VERSION ""

NS_ :

BS_:
BU_: EON XXX RDC SZL VGSG JBBF RFK FLA RAD1 CAS CID AHM HKL HUD EKP DWA DSC SM_BF GWS VDM DDE1 ACI CCC SM_FA CTM LDM RSE MRSZ VDA EDCK ZBE EGS ACC_Sensor Kombi IHKA ARS ACSM FZD PGS NVC AFS DME FRMFA EMF FKA VSW EPS PDC DKG EHC Diagnosetool_PT_CAN Diagnosetool_K_CAN_System ASCM
BO_ 168 Torque1: 8 DME
   SG_ CHK_SUM_TORQ_1_DME : 0|8@1+ (1,0) [0|255] "" XXX
   SG_ ALIV_TORQ_1_DME : 8|4@1+ (1,0) [0|1] "" XXX
   SG_ TORQ_AVL : 11|12@1- (0.5,0) [-1024|1023] "Nm" XXX
   SG_ ST_TORQ_AVL : 24|4@1+ (1,0) [-1024|1023.97] "" XXX
   SG_ TORQ_AVL_DMEE : 28|12@1- (0.5,0) [0|255] "Nm" XXX
   SG_ ST_DMEA_SWO : 44|2@1+ (1,0) [0|255] "" XXX
   SG_ RCPT_ACC_SWO_SYS_DME : 46|2@1+ (1,0) [0|255] "" XXX
   SG_ ST_RCPT_ENG_ACC : 48|2@1+ (1,0) [0|255] "" XXX
   SG_ ST_RCPT_ENG_ARS : 50|2@1+ (1,0) [0|255] "" XXX
   SG_ ST_RCPT_ENG_DSC : 52|2@1+ (1,0) [0|255] "" XXX
   SG_ ST_RCPT_ENG_EGS : 54|2@1+ (1,0) [0|255] "" XXX
   SG_ ST_OBD_CTFN_GRB : 56|5@1+ (1,0) [0|255] "" XXX
   SG_ ST_CT_BRPD_DME : 61|3@1+ (1,0) [0|255] "" XXX

BO_ 169 Torque2: 8 DME
   SG_ CHK_SUM_TORQ_2_DME : 0|8@1+ (1,0) [0|255] "" XXX
   SG_ ALIV_TORQ_2_DME : 8|4@1+ (1,0) [0|255] "" XXX
   SG_ ST_SW_LEV_RPM : 12|2@1+ (1,0) [0|255] "" XXX
   SG_ ST_INFS : 14|2@1+ (1,0) [0|255] "" XXX
   SG_ TORQ_AVL_MIN : 16|12@1- (0.5,0) [0|255] "Nm" XXX
   SG_ TORQ_AVL_MAX : 16|12@1- (0.5,0) [0|255] "Nm" XXX
   SG_ TORQ_AVL_SPAR_NEG : 16|12@1- (0.5,0) [0|255] "Nm" XXX
   SG_ TORQ_AVL_SPAR_POS : 16|12@1- (0.5,0) [0|255] "Nm" XXX

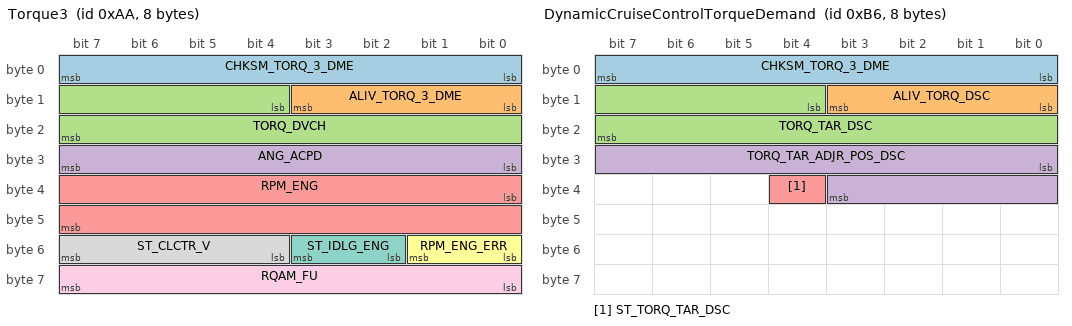
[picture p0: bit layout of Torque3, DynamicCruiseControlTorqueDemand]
BO_ 170 Torque3: 8 DME
   SG_ CHKSM_TORQ_3_DME : 0|8@1+ (1,0) [0|255] "" XXX
   SG_ ALIV_TORQ_3_DME : 8|4@1+ (1,0) [0|255] "" XXX
   SG_ TORQ_DVCH : 12|12@1- (0.5,0) [0|255] "Nm" XXX
   SG_ ANG_ACPD : 24|8@1+ (0.39063,0) [0|255] "%" XXX
   SG_ RPM_ENG : 32|16@1+ (0.25,0) [0|10000] "Rpm" XXX
   SG_ RPM_ENG_ERR : 48|2@1+ (1,0) [0|255] "" XXX
   SG_ ST_IDLG_ENG : 50|2@1+ (1,0) [0|255] "" XXX
   SG_ ST_CLCTR_V : 52|4@1+ (1,0) [0|255] "" XXX
   SG_ RQAM_FU : 56|8@1+ (1,0) [0|255] "" XXX

BO_ 182 DynamicCruiseControlTorqueDemand: 8 DSC
   SG_ CHKSM_TORQ_3_DME : 0|8@1+ (1,0) [0|255] "" XXX
   SG_ ALIV_TORQ_DSC : 8|4@1+ (1,0) [0|255] "" XXX
   SG_ TORQ_TAR_DSC : 12|12@1- (0.5,0) [0|255] "Nm" XXX
   SG_ TORQ_TAR_ADJR_POS_DSC : 24|12@1- (0.5,0) [0|255] "Nm" XXX
   SG_ ST_TORQ_TAR_DSC : 36|1@1+ (1,0) [0|255] "" XXX

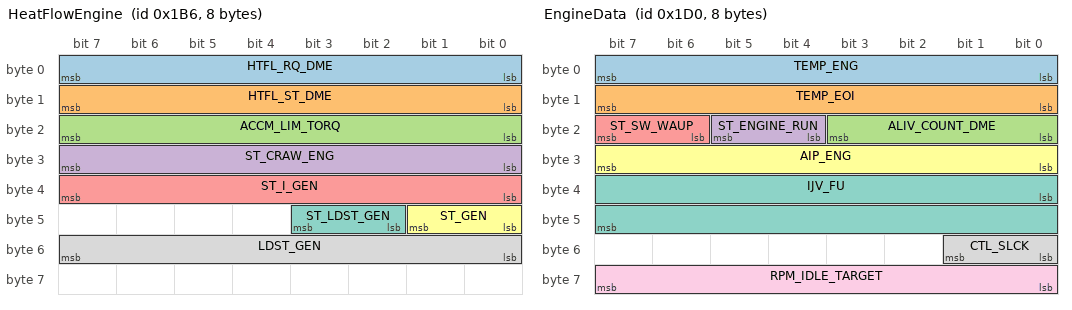
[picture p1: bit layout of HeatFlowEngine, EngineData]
BO_ 438 HeatFlowEngine: 8 DME
   SG_ HTFL_RQ_DME : 0|8@1+ (1,0) [0|255] "" XXX
   SG_ HTFL_ST_DME : 8|8@1+ (1,0) [0|255] "" XXX
   SG_ ACCM_LIM_TORQ : 16|8@1+ (0.5,0) [0|255] "Nm" XXX
   SG_ ST_CRAW_ENG : 24|8@1+ (1,0) [0|255] "A" XXX
   SG_ ST_I_GEN : 32|8@1+ (1,0) [0|255] "A" XXX
   SG_ ST_GEN : 40|2@1+ (1,0) [0|255] "" XXX
   SG_ ST_LDST_GEN : 42|2@1+ (1,0) [0|255] "" XXX
   SG_ LDST_GEN : 48|8@1+ (1,0) [0|255] "%" XXX

BO_ 464 EngineData: 8 DME
   SG_ TEMP_ENG : 0|8@1+ (1,-48) [0|255] "°C" XXX
   SG_ TEMP_EOI : 8|8@1+ (1,-48) [0|255] "°C" XXX
   SG_ ALIV_COUNT_DME : 16|4@1+ (1,0) [0|255] "" XXX
   SG_ ST_ENGINE_RUN : 20|2@1+ (1,0) [0|255] "" XXX
   SG_ ST_SW_WAUP : 22|2@1+ (1,0) [0|255] "" XXX
   SG_ AIP_ENG : 24|8@1+ (2,598) [0|255] "hPa" XXX
   SG_ IJV_FU : 32|16@1+ (1,0) [0|255] "µl" XXX
   SG_ CTL_SLCK : 48|2@1+ (1,0) [0|255] "" XXX
   SG_ RPM_IDLE_TARGET : 56|8@1+ (5,0) [0|255] "Rpm" XXX

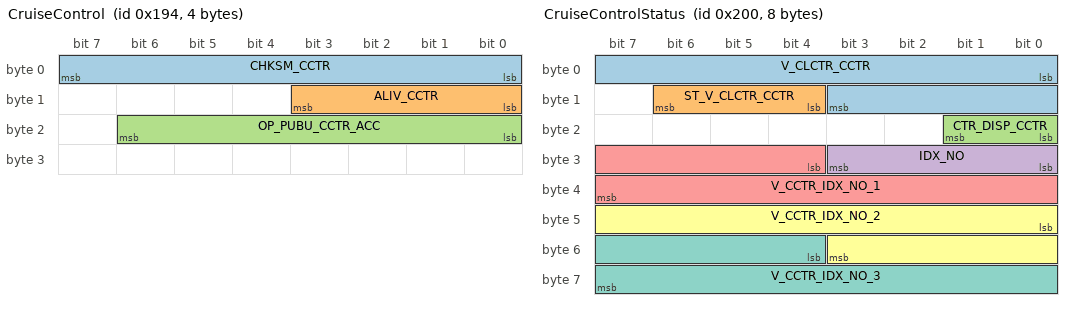
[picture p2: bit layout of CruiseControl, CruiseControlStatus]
BO_ 404 CruiseControl: 4 SZL
   SG_ CHKSM_CCTR : 0|8@1+ (1,0) [0|255] "" XXX
   SG_ ALIV_CCTR : 8|4@1+ (1,0) [0|255] "" XXX
   SG_ OP_PUBU_CCTR_ACC : 16|7@1+ (1,0) [0|255] "" XXX

BO_ 512 CruiseControlStatus: 8 DME
   SG_ V_CLCTR_CCTR : 0|12@1+ (0.1,0) [0|255] "kmph" XXX
   SG_ ST_V_CLCTR_CCTR : 12|3@1+ (1,0) [0|255] "" XXX
   SG_ CTR_DISP_CCTR : 16|2@1+ (0.1,0) [0|255] "kmph" XXX
   SG_ IDX_NO : 24|4@1+ (0.1,0) [0|255] "kmph" XXX
   SG_ V_CCTR_IDX_NO_1 : 28|12@1+ (0.1,0) [0|255] "kmph" XXX
   SG_ V_CCTR_IDX_NO_2 : 40|12@1+ (0.1,0) [0|255] "kmph" XXX
   SG_ V_CCTR_IDX_NO_3 : 52|12@1+ (0.1,0) [0|255] "kmph" XXX

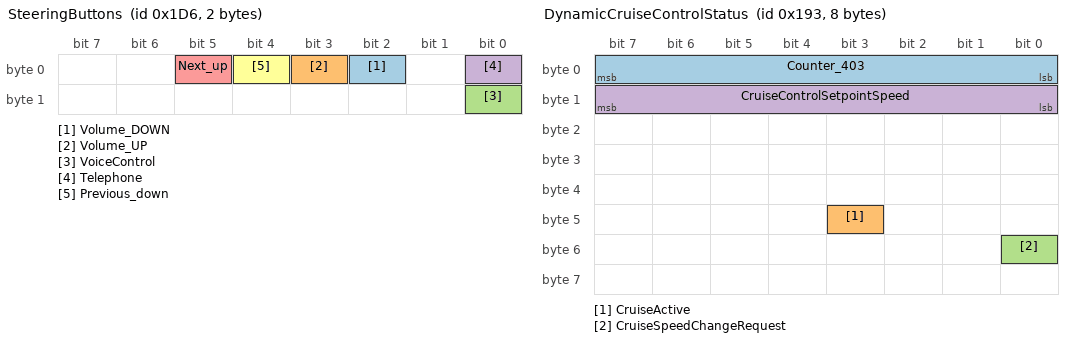
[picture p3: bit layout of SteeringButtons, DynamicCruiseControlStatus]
BO_ 470 SteeringButtons: 2 SZL
   SG_ Volume_DOWN : 2|1@0+ (1,0) [0|1] "" XXX
   SG_ Volume_UP : 3|1@0+ (1,0) [0|1] "" XXX
   SG_ VoiceControl : 8|1@0+ (1,0) [0|1] "" XXX
   SG_ Telephone : 0|1@0+ (1,0) [0|1] "" XXX
   SG_ Next_up : 5|1@0+ (1,0) [0|1] "" XXX
   SG_ Previous_down : 4|1@0+ (1,0) [0|1] "" XXX

BO_ 403 DynamicCruiseControlStatus: 8 DSC
   SG_ Counter_403 : 7|8@0+ (1,0) [0|255] "" XXX
   SG_ CruiseActive : 43|1@0+ (1,0) [0|1] "" XXX
   SG_ CruiseSpeedChangeRequest : 48|1@0+ (1,0) [0|1] "" XXX
   SG_ CruiseControlSetpointSpeed : 15|8@0+ (1,-2) [0|255] "kph/mph" XXX

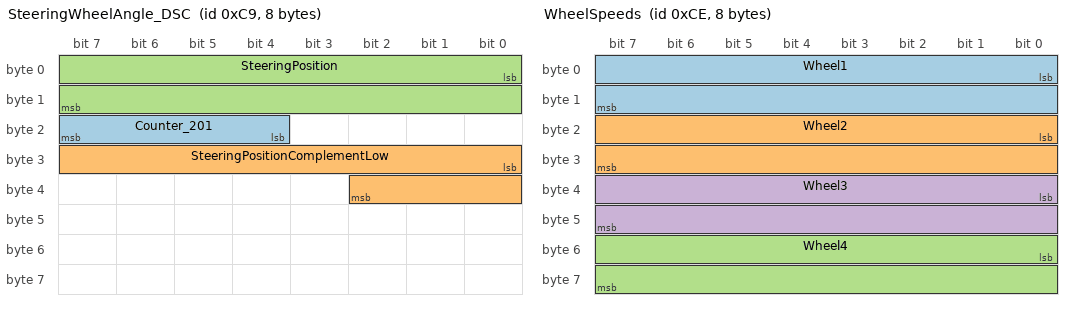
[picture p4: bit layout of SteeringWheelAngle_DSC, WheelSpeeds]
BO_ 201 SteeringWheelAngle_DSC: 8 SZL
   SG_ Counter_201 : 20|4@1+ (1,0) [0|15] "" DSC
   SG_ SteeringPositionComplementLow : 24|11@1- (1,0) [0|1] "" DSC
   SG_ SteeringPosition : 0|16@1- (0.0428317,0) [-600|600] "deg" DSC

BO_ 206 WheelSpeeds: 8 DSC
   SG_ Wheel1 : 0|16@1- (0.0625,0) [0|255] "kph" XXX
   SG_ Wheel2 : 16|16@1- (0.0625,0) [0|255] "kph" XXX
   SG_ Wheel4 : 48|16@1- (0.0625,0) [0|255] "kph" XXX
   SG_ Wheel3 : 32|16@1- (0.0625,0) [0|255] "kph" XXX

BO_ 884 WheelToleranceAdjustment: 8 DSC

BO_ 678 WiperSwitch: 8 SZL
   SG_ AutoWipersOn : 0|1@1+ (1,0) [0|3] "" XXX

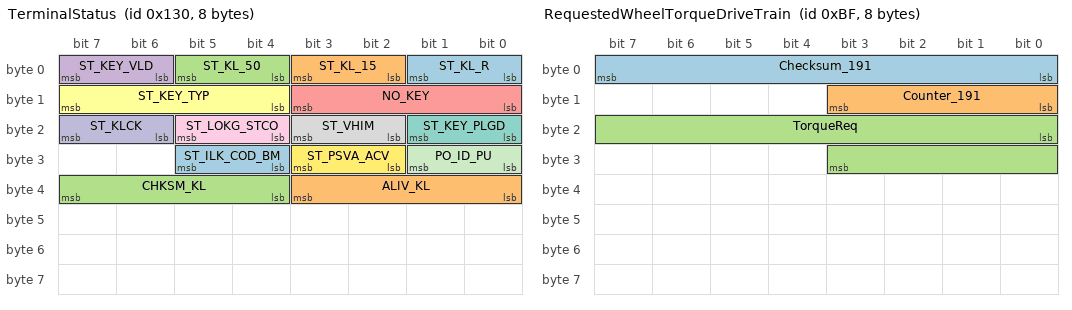
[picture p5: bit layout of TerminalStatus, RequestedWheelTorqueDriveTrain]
BO_ 304 TerminalStatus: 8 CAS
   SG_ ST_KL_R : 0|2@1+ (1,0) [0|3] "" XXX
   SG_ ST_KL_15 : 2|2@1+ (1,0) [0|3] "" XXX
   SG_ ST_KL_50 : 4|2@1+ (1,0) [0|3] "" XXX
   SG_ ST_KEY_VLD : 6|2@1+ (1,0) [0|3] "" XXX
   SG_ NO_KEY : 8|4@1+ (1,0) [0|3] "" XXX
   SG_ ST_KEY_TYP : 12|4@1+ (1,0) [0|3] "" XXX
   SG_ ST_KEY_PLGD : 16|2@1+ (1,0) [0|3] "" XXX
   SG_ ST_VHIM : 18|2@1+ (1,0) [0|3] "" XXX
   SG_ ST_LOKG_STCO : 20|2@1+ (1,0) [0|3] "" XXX
   SG_ ST_KLCK : 22|2@1+ (1,0) [0|3] "" XXX
   SG_ PO_ID_PU : 24|2@1+ (1,0) [0|3] "" XXX
   SG_ ST_PSVA_ACV : 26|2@1+ (1,0) [0|3] "" XXX
   SG_ ST_ILK_COD_BM : 28|2@1+ (1,0) [0|3] "" XXX
   SG_ ALIV_KL : 32|4@1+ (1,0) [0|3] "" XXX
   SG_ CHKSM_KL : 36|4@1+ (1,0) [0|3] "" XXX

BO_ 184 TorqueTransmisionRequest: 8 LDM
   SG_ Checksum_184 : 0|8@1+ (1,0) [0|15] "" XXX
   SG_ Counter_184 : 8|4@1+ (1,0) [0|15] "" XXX

BO_ 196 SteeringWheelAngle: 7 DSC
   SG_ SteeringSpeed : 24|16@1- (0.0428317,0) [0|255] "degree/s" XXX
   SG_ SteeringPosition : 0|16@1- (0.0428317,0) [-600|600] "degree" XXX

BO_ 180 WheelTorqueDriveTrain1: 8 DME

BO_ 186 TransmissionData: 8 EGS
   SG_ Counter_186 : 48|4@1+ (1,0) [0|14] "" XXX
   SG_ Checksum_186 : 40|4@1+ (1,0) [0|15] "" XXX

BO_ 191 RequestedWheelTorqueDriveTrain: 8 LDM
   SG_ Checksum_191 : 0|8@1+ (1,0) [0|19] "" XXX
   SG_ Counter_191 : 8|4@1- (1,0) [0|255] "" XXX
   SG_ TorqueReq : 16|12@1- (0.5,350) [-1024|1023.97] "" XXX

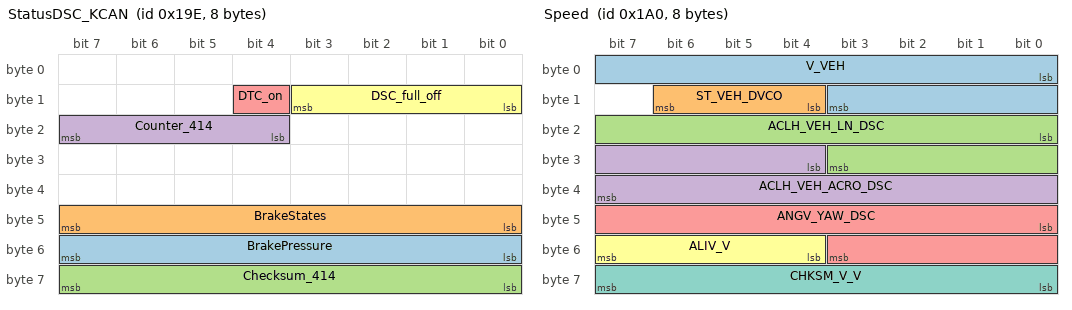
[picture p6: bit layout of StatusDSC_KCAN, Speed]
BO_ 414 StatusDSC_KCAN: 8 DSC
   SG_ BrakePressure : 48|8@1- (1,0) [0|255] "" XXX
   SG_ BrakeStates : 40|8@1+ (1,0) [0|255] "" XXX
   SG_ Checksum_414 : 56|8@1+ (1,0) [0|15] "" XXX
   SG_ Counter_414 : 20|4@1+ (1,0) [0|15] "" XXX
   SG_ DTC_on : 12|1@1+ (1,0) [0|3] "" XXX
   SG_ DSC_full_off : 8|4@1+ (1,0) [0|15] "" XXX

BO_ 416 Speed: 8 DSC
   SG_ V_VEH : 0|12@1+ (0.1,0) [0|255] "kph" XXX
   SG_ ST_VEH_DVCO : 12|3@1+ (1,0) [0|7] "" XXX
   SG_ ACLH_VEH_LN_DSC : 16|12@1- (0.025,0) [0|255] "m/s²" XXX
   SG_ ACLH_VEH_ACRO_DSC : 28|12@1- (0.025,0) [0|255] "m/s²" XXX
   SG_ ANGV_YAW_DSC : 40|12@1- (0.05,0) [0|255] "m/s²" XXX
   SG_ ALIV_V : 52|4@1+ (1,0) [0|14] "" XXX
   SG_ CHKSM_V_V : 56|8@1+ (1,0) [0|15] "" XXX

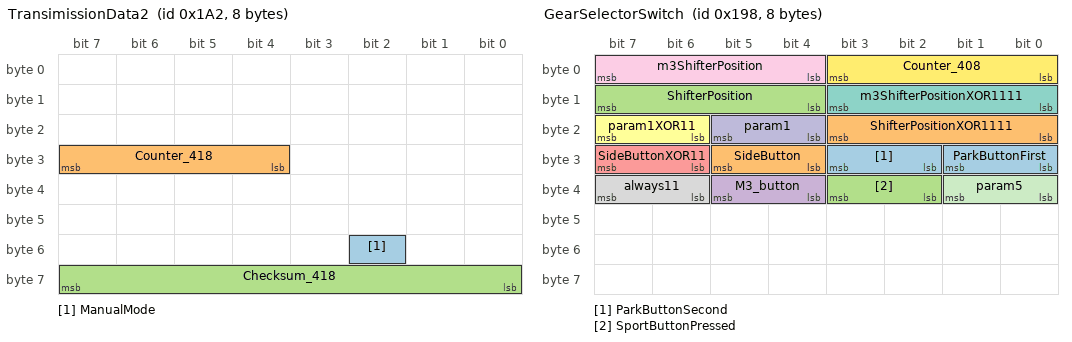
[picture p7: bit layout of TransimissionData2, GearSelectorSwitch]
BO_ 418 TransimissionData2: 8 EGS
   SG_ ManualMode : 50|1@0+ (1,0) [0|255] "" XXX
   SG_ Counter_418 : 28|4@1+ (1,0) [0|14] "" XXX
   SG_ Checksum_418 : 56|8@1+ (1,0) [0|15] "" XXX

BO_ 690 WheelPressure_KCAN: 8 DSC

BO_ 691 AccelerationData: 8 DSC

BO_ 408 GearSelectorSwitch: 8 GWS
   SG_ ParkButtonSecond : 26|2@1+ (1,0) [0|3] "" XXX
   SG_ SideButton : 28|2@1+ (1,0) [0|3] "" XXX
   SG_ SportButtonPressed : 34|2@1+ (1,0) [0|255] "" XXX
   SG_ M3_button : 36|2@1+ (1,0) [0|3] "" XXX
   SG_ SideButtonXOR11 : 30|2@1+ (1,0) [0|3] "" XXX
   SG_ param1XOR11 : 22|2@1+ (1,0) [0|3] "" XXX
   SG_ m3ShifterPositionXOR1111 : 8|4@1+ (1,0) [0|15] "" XXX
   SG_ always11 : 38|2@1+ (1,0) [0|3] "" XXX
   SG_ m3ShifterPosition : 4|4@1+ (1,0) [0|15] "" XXX
   SG_ param1 : 20|2@1+ (1,0) [0|3] "" XXX
   SG_ param5 : 32|2@1+ (1,0) [0|3] "" XXX
   SG_ Counter_408 : 0|4@1+ (1,0) [0|14] "" XXX
   SG_ ParkButtonFirst : 24|2@1+ (1,0) [0|3] "" XXX
   SG_ ShifterPositionXOR1111 : 16|4@1+ (1,0) [0|15] "" XXX
   SG_ ShifterPosition : 12|4@1+ (1,0) [0|0] "" Vector__XXX

BO_ 422 DistanceRoute: 8 DSC

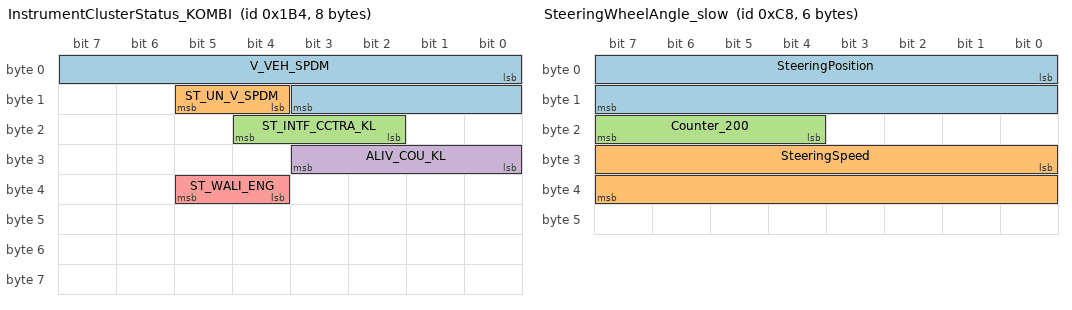
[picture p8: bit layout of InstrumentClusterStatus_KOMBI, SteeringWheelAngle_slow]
BO_ 436 InstrumentClusterStatus_KOMBI: 8 CCC
   SG_ V_VEH_SPDM : 0|12@1+ (0.1,0) [0|255] "kmph" XXX
   SG_ ST_UN_V_SPDM : 12|2@1+ (1,0) [0|255] "" XXX
   SG_ ST_INTF_CCTRA_KL : 18|3@1+ (1,0) [0|255] "" XXX
   SG_ ALIV_COU_KL : 24|4@1+ (1,0) [0|255] "" XXX
   SG_ ST_WALI_ENG : 36|2@1+ (1,0) [0|255] "" XXX

BO_ 945 TransmissionData3: 8 DKG
   SG_ Checksum_946 : 0|8@1+ (1,0) [0|19] "" XXX
   SG_ Counter_945 : 8|4@1+ (1,0) [0|14] "" XXX

BO_ 200 SteeringWheelAngle_slow: 6 SZL
   SG_ SteeringPosition : 0|16@1- (0.0428317,0) [-600|600] "degree" XXX
   SG_ SteeringSpeed : 24|16@1- (0.0428317,0) [-65535|65535] "degree/s" XXX
   SG_ Counter_200 : 20|4@1+ (1,0) [0|15] "" XXX

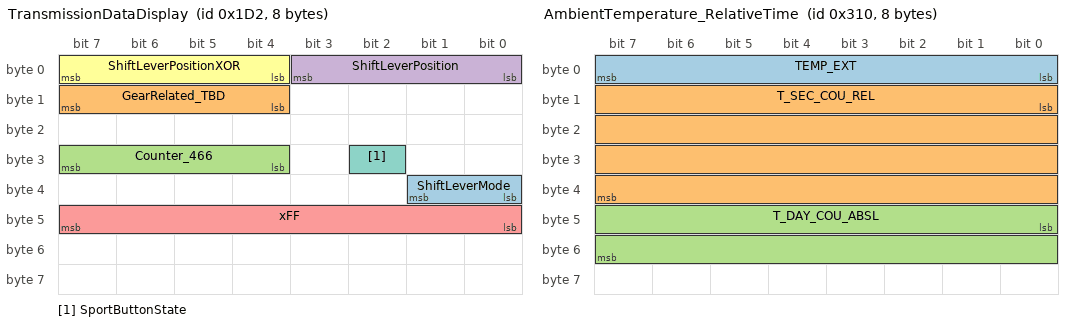
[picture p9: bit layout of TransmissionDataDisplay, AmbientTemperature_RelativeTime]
BO_ 466 TransmissionDataDisplay: 8 EGS
   SG_ ShiftLeverMode : 32|2@1+ (1,0) [0|3] "" XXX
   SG_ GearRelated_TBD : 12|4@1+ (1,0) [0|15] "" XXX
   SG_ Counter_466 : 28|4@1+ (1,0) [0|14] "" XXX
   SG_ ShiftLeverPosition : 0|4@1+ (1,0) [0|8] "" XXX
   SG_ xFF : 40|8@1+ (1,0) [0|255] "" XXX
   SG_ ShiftLeverPositionXOR : 4|4@1+ (1,0) [0|0] "" Vector__XXX
   SG_ SportButtonState : 26|1@1+ (1,0) [0|1] "" XXX

BO_ 437 HeatFlow_LoadTorqueClimate: 8 IHKA
   SG_ HTFL_RQ_AIC : 0|8@1+ (1,0) [0|255] "" XXX
   SG_ HTFL_ST_AIC : 8|8@1+ (1,0) [0|255] "" XXX
   SG_ TORQ_TAR_ACCM : 16|8@1+ (0.5,0) [0|255] "Nm" XXX
   SG_ CTR_EFAN_AIC : 24|4@1+ (1,0) [0|255] "" XXX
   SG_ CTR_AIC_SPFN : 28|2@1+ (1,0) [0|255] "" XXX
   SG_ CTR_CLMP : 32|2@1+ (1,0) [0|255] "" XXX
   SG_ CTR_AIC_RDI : 32|3@1+ (1,0) [0|255] "" XXX

BO_ 1152 NetworkManagment1: 8 XXX

BO_ 1170 NetworkManagment2: 8 XXX

BO_ 1175 NetworkManagment3: 8 XXX

BO_ 1176 NetworkManagment4: 8 XXX

BO_ 1193 NetworkManagment5: 8 XXX

BO_ 1246 GWS_ShiftLeverHeartbeat: 8 XXX
   SG_ IgnOff : 12|1@0+ (1,0) [0|3] "" XXX

BO_ 784 AmbientTemperature_RelativeTime: 8 Kombi
   SG_ TEMP_EXT : 0|8@1+ (0.5,40) [0|255] "°C" XXX
   SG_ T_SEC_COU_REL : 8|32@1+ (1,0) [0|255] "" XXX
   SG_ T_DAY_COU_ABSL : 40|16@1+ (1,0) [0|255] "" XXX

BO_ 821 ElectricFuelPumpStatus: 8 EKP

BO_ 1007 EngineOBD_data: 8 DME

BO_ 1432 ServicesDKG: 8 XXX

BO_ 309 CrashDisconnectControl: 8 ACSM

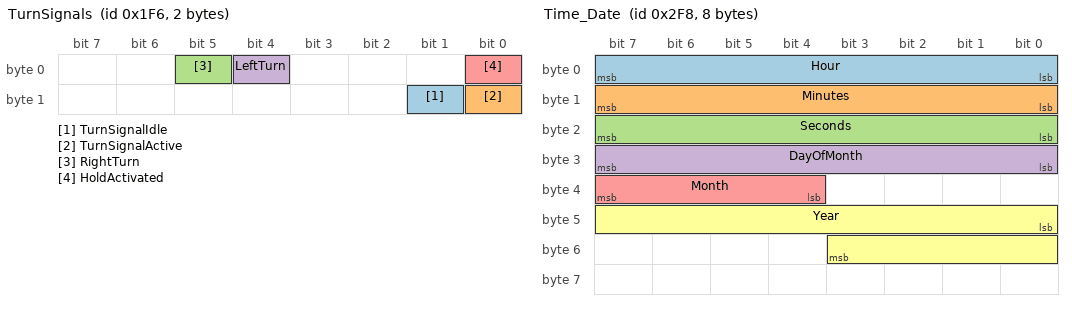
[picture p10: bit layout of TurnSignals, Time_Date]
BO_ 502 TurnSignals: 2 FRMFA
   SG_ TurnSignalIdle : 9|1@0+ (1,0) [0|1] "" XXX
   SG_ TurnSignalActive : 8|1@0+ (1,0) [0|1] "" XXX
   SG_ RightTurn : 5|1@0+ (1,0) [0|1] "" XXX
   SG_ LeftTurn : 4|1@1+ (1,0) [0|1] "" XXX
   SG_ HoldActivated : 0|1@1+ (1,0) [0|1] "" XXX

BO_ 514 Dimming: 8 FRMFA

BO_ 538 LampStatus: 8 FRMFA

BO_ 550 RainSensorWiperSpeed: 8 FZD

BO_ 578 ClimateFrontStatus: 8 IHKA
   SG_ AC_button : 0|1@1+ (1,0) [0|0] "" Vector__XXX
   SG_ Blowers : 8|1@1+ (1,0) [0|0] "" Vector__XXX

BO_ 704 LCD_lighting: 8 Kombi

BO_ 758 LightControl: 8 FRMFA

BO_ 760 Time_Date: 8 Kombi
   SG_ Hour : 0|8@1+ (1,0) [0|0] "" Vector__XXX
   SG_ Minutes : 8|8@1+ (1,0) [0|0] "" Vector__XXX
   SG_ Seconds : 16|8@1+ (1,0) [0|0] "" Vector__XXX
   SG_ DayOfMonth : 24|8@1+ (1,0) [0|0] "" Vector__XXX
   SG_ Month : 36|4@1+ (1,0) [0|0] "" Vector__XXX
   SG_ Year : 40|12@1+ (1,0) [0|0] "" Vector__XXX

BO_ 762 OccupancySeatBeltContact: 8 ACSM
   SG_ NEW_SIGNAL_1 : 8|8@1+ (1,0) [0|255] "" XXX
   SG_ NEW_SIGNAL_2 : 0|8@1+ (1,0) [0|15] "" XXX

BO_ 764 TrunkStatus: 8 CAS
   SG_ DOOR_STATUS : 8|8@1+ (1,0) [0|255] "" XXX
   SG_ BOOT_BONNET_STATUS : 16|8@1+ (1,0) [0|255] "" XXX

BO_ 797 TirePressureStatus: 8 DSC

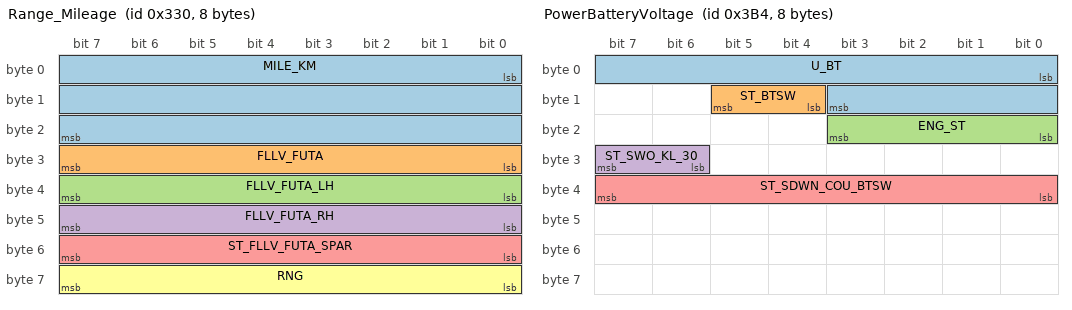
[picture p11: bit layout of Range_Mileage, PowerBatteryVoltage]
BO_ 816 Range_Mileage: 8 Kombi
   SG_ MILE_KM : 0|24@1+ (1,0) [0|15] "Km" XXX
   SG_ FLLV_FUTA : 24|8@1+ (1,0) [0|15] "" XXX
   SG_ FLLV_FUTA_LH : 32|8@1+ (0.5,0) [0|15] "L" XXX
   SG_ FLLV_FUTA_RH : 40|8@1+ (0.5,0) [0|15] "L" XXX
   SG_ ST_FLLV_FUTA_SPAR : 48|8@1+ (1,0) [0|255] "" XXX
   SG_ RNG : 56|8@1+ (1,0) [0|15] "km" XXX

BO_ 823 StatusFuelControl: 8 DME

BO_ 897 EngineOilLevel: 8 DME

BO_ 940 RunOnTimeTerminal30: 8 JBBF

BO_ 947 PowerManagmentConsumptionControl: 8 DME

BO_ 948 PowerBatteryVoltage: 8 DME
   SG_ U_BT : 0|12@1+ (0.015,0) [0|65535] "V" XXX
   SG_ ST_BTSW : 12|2@1+ (1,0) [0|3] "" XXX
   SG_ ENG_ST : 16|4@1+ (1,0) [0|12] "" XXX
   SG_ ST_SWO_KL_30 : 30|2@1+ (1,0) [0|3] "" XXX
   SG_ ST_SDWN_COU_BTSW : 32|8@1+ (1,0) [0|3] "" XXX

BO_ 958 PowerRunningTime: 8 CAS

BO_ 1408 ServicesKGM: 8 XXX

BO_ 1426 ServicesDME: 8 XXX

BO_ 1449 ServicesDSC: 8 XXX

BO_ 1504 ServicesKOMBI: 8 XXX

BO_ 1522 ServicesKBM: 8 XXX

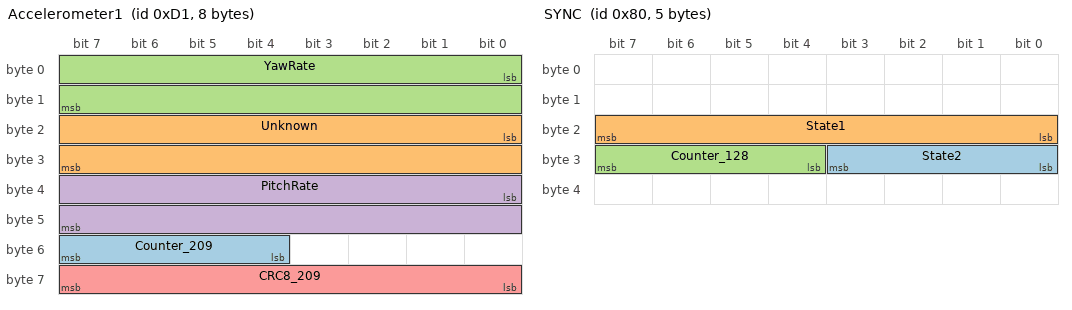
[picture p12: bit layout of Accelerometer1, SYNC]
BO_ 209 Accelerometer1: 8 XXX
   SG_ Counter_209 : 52|4@1+ (1,0) [0|255] "" XXX
   SG_ Unknown : 16|16@1- (1,0) [0|65535] "" XXX
   SG_ YawRate : 0|16@1- (1,0) [0|7] "" XXX
   SG_ PitchRate : 32|16@1- (1,0) [0|65535] "" XXX
   SG_ CRC8_209 : 56|8@1+ (1,0) [0|255] "" XXX

BO_ 172 WheelTorqueDrivetrain2: 8 DME

BO_ 128 SYNC: 5 XXX
   SG_ State2 : 24|4@1+ (1,0) [0|15] "" XXX
   SG_ State1 : 16|8@1+ (1,0) [0|255] "" XXX
   SG_ Counter_128 : 28|4@1+ (1,0) [0|15] "" XXX

BO_ 320 Unknown140: 2 XXX
   SG_ State : 7|8@0+ (1,0) [0|255] "" XXX

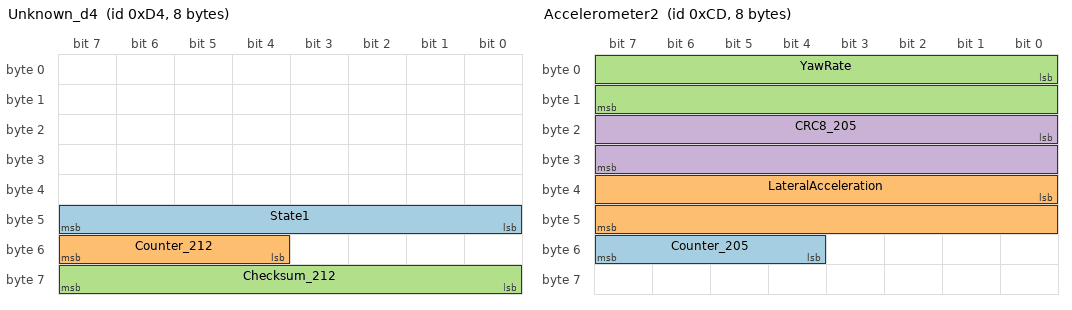
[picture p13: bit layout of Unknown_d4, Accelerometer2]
BO_ 212 Unknown_d4: 8 XXX
   SG_ State1 : 40|8@1+ (1,0) [0|255] "" XXX
   SG_ Counter_212 : 52|4@1+ (1,0) [0|255] "" XXX
   SG_ Checksum_212 : 56|8@1+ (1,0) [0|255] "" XXX

BO_ 205 Accelerometer2: 8 XXX
   SG_ Counter_205 : 52|4@1+ (1,0) [0|255] "" XXX
   SG_ LateralAcceleration : 32|16@1- (1,0) [0|255] "" XXX
   SG_ YawRate : 0|16@1- (1,0) [0|255] "" XXX
   SG_ CRC8_205 : 16|16@1- (1,0) [0|65535] "" XXX

BO_ 790 OperationPushButtonDTC: 2 JBBF
   SG_ setMe_0x3FFF : 2|14@1+ (1,0) [0|63] "" DSC
   SG_ DTC_pressed : 0|1@1+ (1,0) [0|3] "" DSC

BO_ 1577 Unknown_629: 8 XXX

BO_ 133 Synchronization_SC_VDA: 8 DSC

BO_ 173 Delay_request_ACC: 8 LDM

BO_ 177 Torque_request_steering: 8 DSC

BO_ 181 Torque_request_EGS: 8 EGS

BO_ 183 Torque_request_ACC: 8 LDM

BO_ 187 Target_torque_request: 8 DSC

BO_ 188 Status_target_torque_conversion: 8 VGSG

BO_ 190 Alive_Counter: 8 ARS

BO_ 192 Alive_Central_Gateway: 8 JBBF

BO_ 193 Alive_counter_telephone: 8 CCC

BO_ 213 Request_wheel_torque_brake: 8 DSC

BO_ 215 Alive_Counter_Security: 8 ACSM

BO_ 216 CLU1_VDA: 8 VDA

BO_ 225 Wheel_torque_brake: 8 DSC

BO_ 226 Status_central_locking_BFT: 8 JBBF

BO_ 227 CLU2_VDA: 8 VDA

BO_ 230 Status_central_locking_BFTH: 8 JBBF

BO_ 234 Status_central_locking_FAT: 8 JBBF

BO_ 238 Central_locking_status_FATH: 8 JBBF

BO_ 242 Status_central_locking_HK: 8 JBBF

BO_ 244 CLU3_VDA: 8 VDA

BO_ 247 lateral_dynamics_ARS_VDM: 8 ARS

BO_ 249 Vertical_dynamics_VDM_ARS: 8 VDM

BO_ 250 Control_window_lifter_FAT: 8 FRMFA

BO_ 251 Control_window_lifter_BFT: 8 JBBF

BO_ 252 Control_window_lifter_FATH: 8 JBBF

BO_ 253 Control_window_lifter_BFTH: 8 JBBF

BO_ 254 Voltage_level_sensors: 8 VDM

BO_ 280 Exchange_AFS_DSC: 8 AFS

BO_ 286 Control_interventions_DSC_AFS: 8 DSC

BO_ 288 Status_partial_setpoints_AFS_DSC: 8 AFS

BO_ 298 Sensor_data_ROSE: 8 ASCM

BO_ 300 input_data_ROSE: 8 DSC

BO_ 336 Request_1_ACC: 8 LDM

BO_ 339 Request_2_ACC: 8 LDM

BO_ 345 Object_data_ACC: 8 ACC_Sensor

BO_ 348 Status_ACC: 8 ACC_Sensor

BO_ 351 Requirement_angle_FFP: 8 LDM

BO_ 357 CLU_Status_VDA: 8 VDA

BO_ 370 Acknowledgment_request_Kombinati: 8 CCC

BO_ 373 Display_motor_data: 8 DME

BO_ 400 display_ACC: 8 LDM

BO_ 405 Operation_push_button_MSA: 8 IHKA

BO_ 419 Raw_data_longitudinal_accelerati: 8 DSC

BO_ 423 actuation_request_EMF: 8 DSC

BO_ 426 Effect_ErgoCommander: 8 CCC

BO_ 428 Status_ARS_module: 8 ARS

BO_ 440 Operation_ErgoCommander: 8 ZBE

BO_ 450 Distance_message_PDC: 8 PDC

BO_ 451 Distance_message_2_PDC: 8 PDC

BO_ 454 Acoustic_message_PDC: 8 PDC

BO_ 472 Operation_air_conditioning_air_d: 8 CCC

BO_ 473 Operation_pushbutton_MDrive: 8 SZL

BO_ 474 Climate_control_remote_control: 8 CAS

BO_ 476 Operation_stratification_seat_he: 8 CCC

BO_ 478 Air_conditioning_controls_rear: 8 CCC

BO_ 480 Operation_air_conditioning__0000: 8 CCC

BO_ 482 Operation_air_conditioning_front: 8 CCC

BO_ 483 Operation_pushbutton_interior_li: 8 FZD

BO_ 487 Operation_seat_heating_seat_clim: 8 IHKA

BO_ 488 Operation_seat_heating_seat_0000: 8 IHKA

BO_ 490 Steering_column_adjustment_contr: 8 IHKA

BO_ 491 Operation_active_seat_FA: 8 IHKA

BO_ 492 Operation_active_seat_BF: 8 IHKA

BO_ 494 Steering_column_switch_operation: 8 FRMFA

BO_ 499 Operation_seat_memory_FA: 8 XXX

BO_ 504 Operation_SHD_MDS: 8 FZD

BO_ 507 Status_EPS: 8 EPS

BO_ 508 Status_AFS: 8 AFS

BO_ 509 Status_request_EMF_KCAN: 8 EMF

BO_ 510 Crash: 8 ACSM

BO_ 513 Status_EMF_KCAN: 8 EMF

BO_ 517 Acoustic_request_Kombi: 8 Kombi

BO_ 518 Control_Display_Shiftlights: 8 DME

BO_ 523 Memory_adjustment: 8 SM_FA

BO_ 524 Steering_column_control: 8 SM_FA

BO_ 525 Position_steering_column: 8 IHKA

BO_ 528 Operation_HUD: 8 CCC

BO_ 529 Status_HUD: 8 HUD

BO_ 530 Height_levels_air_spring: 8 EHC

BO_ 540 Operation_NightVision: 8 CCC

BO_ 542 Status_NightVision: 8 NVC

BO_ 548 Operation_push_button_NSW: 8 FRMFA

BO_ 552 Operation_special_function: 8 CCC

BO_ 554 Status_BFS: 8 JBBF

BO_ 556 Operation_push_button_NSL: 8 FRMFA

BO_ 558 Status_BFSH: 8 XXX

BO_ 562 Status_FAS: 8 JBBF

BO_ 566 Status_FASH: 8 XXX

BO_ 570 Status_radio_key: 8 CAS

BO_ 571 Status_climate_front_extended: 8 IHKA

BO_ 573 Request_display_climate: 8 IHKA

BO_ 574 Status_Klima_Fond: 8 FKA

BO_ 582 Status_air_conditioning_front_co: 8 IHKA

BO_ 584 Status_rear_view_camera: 8 RFK

BO_ 585 Control_rear_view_camera: 8 CCC

BO_ 586 Status_PDC: 8 PDC

BO_ 587 Status_door_sensors: 8 FRMFA

BO_ 594 Wiper_status: 8 JBBF

BO_ 598 Challenge_Passive_Access: 8 CAS

BO_ 600 Status_Transmission_Passive_Acce: 8 PGS

BO_ 604 Operation_of_climate_additional_: 8 CCC

BO_ 621 Operation_blinds_MK: 8 IHKA

BO_ 622 Control_FH_SHD_central_comfort: 8 CAS

BO_ 635 Status_Shiftlights: 8 Kombi

BO_ 637 Status_convertible_top_manual_co: 8 CAS

BO_ 638 Status_convertible_top_convertib: 8 CTM

BO_ 639 Status_central_locking_convertib: 8 JBBF

BO_ 642 Control_security_vehicle_2: 8 XXX

BO_ 644 Control_remote_start_safety_vehi: 8 CAS

BO_ 646 Electrochromic_control: 8 FZD

BO_ 652 Pushbutton_vertical_dynamics: 8 GWS

BO_ 653 Operation_pushbutton_sport: 8 GWS

BO_ 656 Control_response_hydrogen_vehicl: 8 XXX

BO_ 658 Control_high_beam_assistant: 8 FLA

BO_ 670 Central_locking_control_for_secu: 8 XXX

BO_ 671 Remote_control_FondCommander: 8 CAS

BO_ 672 Central_locking_control: 8 CAS

BO_ 674 Operation_of_climate_stand_funct: 8 CCC

BO_ 676 Operation_personalization: 8 Kombi

BO_ 692 DWA_Alarm: 8 DWA

BO_ 694 Control_horn_DWA: 8 DWA

BO_ 696 Operation_onboard_computer: 8 CCC

BO_ 697 Operation_RSE: 8 CCC

BO_ 698 Stopwatch: 8 Kombi

BO_ 701 Request_switching_display: 8 CCC

BO_ 702 Switch_status_display: 8 VSW

BO_ 703 Water_valve_control: 8 IHKA

BO_ 706 Temperatur_Ist_Fond: 8 FKA

BO_ 711 Display_Kombination_extended: 8 DME

BO_ 714 Outside_temperature: 8 Kombi

BO_ 716 Control_monitor_rear: 8 RSE

BO_ 718 Control_monitor: 8 CCC

BO_ 719 Status_of_auxiliary_water_pump: 8 JBBF

BO_ 720 Status_Sensor_AUC: 8 JBBF

BO_ 721 Status_fitting_window_V: 8 FZD

BO_ 722 Status_pressure_refrigeration_ci: 8 JBBF

BO_ 723 Status_stratification_rear: 8 JBBF

BO_ 725 Status_heating_rear_window: 8 JBBF

BO_ 726 Status_valve_air_conditioning_co: 8 JBBF

BO_ 730 Status_tailgate_lift: 8 HKL

BO_ 734 Switch_control_display: 8 VSW

BO_ 738 Status_setting_video_night_visio: 8 NVC

BO_ 739 Status_setting_video_rear_view_c: 8 RFK

BO_ 740 Status_trailer: 8 AHM

BO_ 742 Status_of_air_distribution_FA: 8 IHKA

BO_ 746 Status_air_distribution_BF: 8 IHKA

BO_ 750 Status_climate_additional_progra: 8 IHKA

BO_ 752 Status_air_condition_functions: 8 IHKA

BO_ 753 Status_driver_detection: 8 MRSZ

BO_ 755 Display_switching_instruction: 8 DME

BO_ 756 Air_conditioning_control_SH_ZH_a: 8 IHKA

BO_ 759 Units: 8 Kombi

BO_ 768 Status_RSE: 8 RSE

BO_ 772 Status_Gang: 8 EGS

BO_ 773 Operation_button_convertible_top: 8 IHKA

BO_ 774 Vehicle_tilt: 8 FRMFA

BO_ 775 Operation_button_flap_convertibl: 8 IHKA

BO_ 776 Status_MSA: 8 DME

BO_ 785 Refill_quantity: 8 Kombi

BO_ 786 Service_Call_Teleservice: 8 Kombi

BO_ 787 Status_Service_Call_Teleservice: 8 CCC

BO_ 788 Status_driving_light: 8 FZD

BO_ 789 Vehicle_mode: 8 JBBF

BO_ 791 Operation_button_parking_aids: 8 IHKA

BO_ 792 Status_antennas_Passive_Access: 8 PGS

BO_ 793 Operation_push_button_RDC: 8 JBBF

BO_ 794 Operation_button_HDC: 8 IHKA

BO_ 795 Operation_of_tailgate_interior_b: 8 IHKA

BO_ 796 Status_tire_pressure: 8 RDC

BO_ 801 Operation_button_camera_BF: 8 IHKA

BO_ 802 Damper_current: 8 EDCK

BO_ 806 Status_damper_program: 8 VDM

BO_ 808 Relativzeit: 8 Kombi

BO_ 813 Display_HDC: 8 DSC

BO_ 814 Status_climate_internal_control_: 8 IHKA

BO_ 817 Programming_of_step_cruise_contr: 8 CCC

BO_ 818 Driver_display_speed_range: 8 DME

BO_ 822 Display_check_control_message_ro: 8 Kombi

BO_ 824 Control_display_check_control_me: 8 Kombi

BO_ 825 Status_display_climate: 8 CCC

BO_ 826 Status_Monitor_Front: 8 CID

BO_ 828 Status_Monitor_Fond_1: 8 CID

BO_ 830 Status_Monitor_Fond_2: 8 CID

BO_ 841 Raw_data_level_tank: 8 JBBF

BO_ 843 Seat_back_lock_status_FA: 8 SM_FA

BO_ 845 Status_seat_back_lock_BF: 8 SM_BF

BO_ 847 Status_contact_handbrake: 8 JBBF
   SG_ ST_HandBrake_Cont : 0|2@1+ (1,0) [0|3] "" XXX

BO_ 858 Appointment_Condition_Based_Serv: 8 CCC

BO_ 860 Status_onboard_computer: 8 Kombi

BO_ 862 Onboard_computer_data_trip_data: 8 Kombi

BO_ 864 Data_onboard_computer_start_of_j: 8 Kombi

BO_ 866 Data_onboard_computer_average_va: 8 Kombi

BO_ 868 Data_onboard_computer_arrival: 8 Kombi

BO_ 869 Status_terminal_request: 8 CAS

BO_ 870 Display_Kombination_external_dis: 8 Kombi

BO_ 871 Control_display_of_demand_orient: 8 Kombi

BO_ 877 Setting_the_driving_dynamics_swi: 8 JBBF

BO_ 886 Status_wear_lamella: 8 VGSG

BO_ 893 Status_DKG: 8 DKG

BO_ 894 Temperatur_Bremse: 8 DSC

BO_ 895 Range_of_diesel_exhaust_gas_addi: 8 DDE1

BO_ 896 chassis_number: 8 CAS

BO_ 898 Electronic_engine_oil_dipstick_M: 8 DME

BO_ 899 Motor_data_2: 8 DME

BO_ 904 Vehicle_type: 8 CAS

BO_ 907 Status_battery: 8 DME

BO_ 910 Start_speed: 8 DME

BO_ 914 Status_System_AFS: 8 AFS

BO_ 916 RDA_request_data_storage: 8 Kombi

BO_ 917 Coding_power_management: 8 CAS

BO_ 920 Operation_chassis: 8 CCC

BO_ 921 Status_MDrive: 6 DME

BO_ 926 Operation_time_date: 8 CCC

BO_ 928 Vehicle_state: 8 JBBF

BO_ 931 Request_Remote_Services: 8 CCC

BO_ 937 Status_motor_control_CKM: 8 DME

BO_ 939 Status_Shiftlights_CKM: 8 Kombi

BO_ 944 Status_gear_reverse: 8 FRMFA
   SG_ ST_Reverse_Gear : 0|2@1+ (1,0) [0|3] "" XXX

BO_ 949 Status_water_valve: 8 JBBF

BO_ 950 Position_window_lifter_FAT: 8 FRMFA

BO_ 951 Position_window_lifter_FATH: 8 JBBF

BO_ 952 Position_window_regulator_BFT: 8 FRMFA

BO_ 953 Position_window_regulator_BFTH: 8 JBBF

BO_ 954 Position_SHD: 8 FZD

BO_ 956 Position_window_lifter_security_: 8 XXX

BO_ 957 Status_consumer_shutdown: 8 FRMFA

BO_ 959 Position_window_rear_window: 8 CTM

BO_ 960 Configuration_FAS: 8 SM_FA

BO_ 961 Configuration_BFS: 8 SM_BF

BO_ 964 Status_EDCK_CKM: 8 JBBF

BO_ 967 Access_radio: 8 RAD1

BO_ 968 Operation_push_button_radio: 8 RAD1

BO_ 974 Radio_audio_control_interface_di: 8 ACI

BO_ 975 Acknowledgment_access_radio_audi: 8 ACI

BO_ 979 Status_solar_sensor: 8 FZD

BO_ 980 Configuration_of_central_locking: 8 Kombi

BO_ 981 Status_central_locking_CKM: 8 CAS

BO_ 982 Configuration_DWA_CKM: 8 Kombi

BO_ 983 Status_DWA_CKM: 8 FZD

BO_ 984 Configuration_RLS_CKM: 8 Kombi

BO_ 985 Status_RLS_CKM: 8 FZD

BO_ 986 Configuration_of_memory_position: 8 Kombi

BO_ 987 Status_memory_positions_CKM: 8 SM_FA

BO_ 988 Configuration_light_CKM: 8 Kombi

BO_ 989 Status_light_CKM: 8 FRMFA

BO_ 990 Configuration_Climate_CKM: 8 CCC

BO_ 991 Status_Klima_CKM: 8 IHKA

BO_ 994 Configuration_of_tailgate_CKM: 8 CCC

BO_ 995 Status_tailgate_CKM: 8 HKL

BO_ 996 Configuration_rear_view_camera_C: 8 CCC

BA_DEF_ BO_ "SystemMessageLongSymbol" STRING ;
BA_DEF_ BO_ "GenMsgBackgroundColor" STRING ;
BA_DEF_ BO_ "GenMsgForegroundColor" STRING ;
BA_ "SystemMessageLongSymbol" BO_ 288 "Status_partial_setpoints_AFS_DSC_2";
BA_ "SystemMessageLongSymbol" BO_ 370 "Acknowledgment_request_Kombination";
BA_ "SystemMessageLongSymbol" BO_ 419 "Raw_data_longitudinal_acceleration";
BA_ "SystemMessageLongSymbol" BO_ 472 "Operation_air_conditioning_air_distribution_FA";
BA_ "SystemMessageLongSymbol" BO_ 476 "Operation_stratification_seat_heating";
BA_ "SystemMessageLongSymbol" BO_ 480 "Operation_air_conditioning_air_distribution_BF";
BA_ "SystemMessageLongSymbol" BO_ 483 "Operation_pushbutton_interior_lighting";
BA_ "SystemMessageLongSymbol" BO_ 487 "Operation_seat_heating_seat_climate_FA";
BA_ "SystemMessageLongSymbol" BO_ 488 "Operation_seat_heating_seat_climate_BF";
BA_ "SystemMessageLongSymbol" BO_ 490 "Steering_column_adjustment_control";
BA_ "SystemMessageLongSymbol" BO_ 582 "Status_air_conditioning_front_control_unit";
BA_ "SystemMessageLongSymbol" BO_ 600 "Status_Transmission_Passive_Access";
BA_ "SystemMessageLongSymbol" BO_ 604 "Operation_of_climate_additional_programs";
BA_ "SystemMessageLongSymbol" BO_ 637 "Status_convertible_top_manual_convertible";
BA_ "SystemMessageLongSymbol" BO_ 638 "Status_convertible_top_convertible";
BA_ "SystemMessageLongSymbol" BO_ 639 "Status_central_locking_convertible_top";
BA_ "SystemMessageLongSymbol" BO_ 644 "Control_remote_start_safety_vehicle";
BA_ "SystemMessageLongSymbol" BO_ 656 "Control_response_hydrogen_vehicle";
BA_ "SystemMessageLongSymbol" BO_ 670 "Central_locking_control_for_security_vehicle";
BA_ "SystemMessageLongSymbol" BO_ 674 "Operation_of_climate_stand_functions";
BA_ "SystemMessageLongSymbol" BO_ 722 "Status_pressure_refrigeration_circuit";
BA_ "SystemMessageLongSymbol" BO_ 726 "Status_valve_air_conditioning_compressor";
BA_ "SystemMessageLongSymbol" BO_ 738 "Status_setting_video_night_vision";
BA_ "SystemMessageLongSymbol" BO_ 739 "Status_setting_video_rear_view_camera";
BA_ "SystemMessageLongSymbol" BO_ 750 "Status_climate_additional_programs";
BA_ "SystemMessageLongSymbol" BO_ 756 "Air_conditioning_control_SH_ZH_auxiliary_water_pump";
BA_ "SystemMessageLongSymbol" BO_ 775 "Operation_button_flap_convertible_top";
BA_ "SystemMessageLongSymbol" BO_ 795 "Operation_of_tailgate_interior_button";
BA_ "SystemMessageLongSymbol" BO_ 814 "Status_climate_internal_control_info";
BA_ "SystemMessageLongSymbol" BO_ 817 "Programming_of_step_cruise_control";
BA_ "SystemMessageLongSymbol" BO_ 822 "Display_check_control_message_role";
BA_ "SystemMessageLongSymbol" BO_ 824 "Control_display_check_control_message";
BA_ "SystemMessageLongSymbol" BO_ 858 "Appointment_Condition_Based_Service";
BA_ "SystemMessageLongSymbol" BO_ 864 "Data_onboard_computer_start_of_journey";
BA_ "SystemMessageLongSymbol" BO_ 866 "Data_onboard_computer_average_values";
BA_ "SystemMessageLongSymbol" BO_ 870 "Display_Kombination_external_display";
BA_ "SystemMessageLongSymbol" BO_ 871 "Control_display_of_demand_oriented_service";
BA_ "SystemMessageLongSymbol" BO_ 877 "Setting_the_driving_dynamics_switch";
BA_ "SystemMessageLongSymbol" BO_ 895 "Range_of_diesel_exhaust_gas_additive";
BA_ "SystemMessageLongSymbol" BO_ 956 "Position_window_lifter_security_vehicle";
BA_ "SystemMessageLongSymbol" BO_ 974 "Radio_audio_control_interface_display";
BA_ "SystemMessageLongSymbol" BO_ 975 "Acknowledgment_access_radio_audio_control_interface";
BA_ "SystemMessageLongSymbol" BO_ 980 "Configuration_of_central_locking_CKM";
BA_ "SystemMessageLongSymbol" BO_ 986 "Configuration_of_memory_positions_CKM";
BA_ "SystemMessageLongSymbol" BO_ 996 "Configuration_rear_view_camera_CKM";
BA_DEF_DEF_ "SystemMessageLongSymbol" "";
BA_DEF_DEF_ "GenMsgBackgroundColor" "#ffffff";
BA_DEF_DEF_ "GenMsgForegroundColor" "#000000";
CM_ SG_ 408 ParkButtonSecond "Redundant buton. 0x1 = pressed;";
CM_ SG_ 408 SideButton "0x1 = pressed;";
CM_ SG_ 408 SportButtonPressed "0x1 = pressed;";
CM_ SG_ 408 M3_button "M3 POWER (?)";
CM_ SG_ 408 SideButtonXOR11 "Complement value";
CM_ SG_ 408 param1 "can not be 0x03. Always 0 in 135i.";
CM_ SG_ 408 param5 "Always 0 in 135i.";
CM_ SG_ 408 ParkButtonFirst "0x1 = pressed";
CM_ SG_ 408 ShifterPosition "0001 = N|R, 0010 = R, 0011 = N|D, 0100 = D, 0101 = -1, 0110 = +1, 0111 = ManualMode, 1000 = inBetween,";
CM_ SG_ 466 ShiftLeverMode "On the dashboard, there are displayed: D1...D7 in Normal. S1...S6 in Sport. M1..M7 in Manual";
CM_ SG_ 502 TurnSignalIdle "Turn signal off";
CM_ SG_ 502 TurnSignalActive "Turn signal on or transitioning";
CM_ SG_ 502 RightTurn "Indicates right blinker or when steering returning right clears left blinker";
CM_ SG_ 502 LeftTurn "Indicates left blinker or when steering returning left clears right blinker";
CM_ SG_ 502 HoldActivated "Spikes down if blinker cleared with timeout or turn. Stays off if blinker cleared with stalk";
CM_ SG_ 816 MILE_KM "mileage in km or mls";
CM_ SG_ 816 FLLV_FUTA "total fuel amount";
CM_ SG_ 816 FLLV_FUTA_LH "total fuel amount in Left tank half";
CM_ SG_ 816 FLLV_FUTA_RH "total fuel amount in right tank half";
CM_ SG_ 816 ST_FLLV_FUTA_SPAR "reserve indicator";
CM_ SG_ 816 RNG "range in km or mls";
CM_ SG_ 790 setMe_0x3FFF "All ones";
CM_ SG_ 790 DTC_pressed "Traction control off. Message transmitted when pressed. Few presses may be required followed by off.";
VAL_ 169 ST_SW_LEV_RPM 1 "Idle Speed Over Threshold" 0 "Idle Speed Under Threshold";
VAL_ 169 ST_INFS 1 "Thrust Cutoff Active" 0 "Not Active";
VAL_ 170 RPM_ENG_ERR 3 "Invalid Signal" 1 "Speed Sensor Defective" 0 "Single OK";
VAL_ 170 ST_IDLG_ENG 3 "Invalid Signal" 1 "No Idle" 0 "Idle";
VAL_ 170 ST_CLCTR_V 11 "pedal kickdown" 10 "pedal transgress" 9 "pedal pressed" 8 "pedal not pressed" 7 "cc regulation, speed up" 6 "cc regulation, recall" 5 "cc regulation, constant speed" 4 "cc regulation, retard" 1 "acc regulation, pedal pressed" 0 "acc regulation, pedal not pressed";
VAL_ 182 ST_TORQ_TAR_DSC 0 "No Torque Request" 1 "Increase Torque" 2 "Decrease Torque" 3 "Signal Invalid";
VAL_ 438 ST_GEN 3 "Invalid Signal" 2 "Error" 1 "High Temp Limit" 0 "OK";
VAL_ 438 ST_LDST_GEN 3 "Invalid Signal" 2 "Utilization 100%" 1 "Utilization 50%-100%" 0 "Utilization 0%-50%";
VAL_ 464 ST_ENGINE_RUN 0 "Engine Off" 1 "Engine Starting" 2 "Engine Running" 3 "Signal Invalid";
VAL_ 464 ST_SW_WAUP 0 "Engine Warming Up" 1 "Engine Warm" 2 "EGS Forced Switching Active" 3 "Signal Invalid";
VAL_ 464 CTL_SLCK 0 "Inhibited" 1 "No Requirement Shiftlock" 2 "Requirement Shiftlock" 3 "Signal Invalid";
VAL_ 404 OP_PUBU_CCTR_ACC 0 "No Action" 1 "Set/Accelerate" 2 "Step High" 4 "Slow down" 8 "Step Lower" 16 "Off" 64 "Resume" 127 "Invalid Signal";
VAL_ 512 ST_V_CLCTR_CCTR 0 "Cruise Control Off" 1 "Cruise Control Inactive" 2 "Cruise Control Active";
VAL_ 512 CTR_DISP_CCTR 0 "Markers Off" 1 "Markers On";
VAL_ 304 ST_KL_R 0 "Off" 1 "On" 2 "Signal Invalid";
VAL_ 304 ST_KL_15 0 "Off" 1 "On" 2 "Signal Invalid";
VAL_ 304 ST_KL_50 0 "Off" 1 "On" 2 "Signal Invalid";
VAL_ 304 ST_KEY_VLD 0 "Off" 1 "On" 2 "Signal Invalid";
VAL_ 304 ST_KEY_PLGD 0 "Off" 1 "On" 2 "Signal Invalid";
VAL_ 304 ST_VHIM 0 "Off" 1 "On" 2 "Signal Invalid";
VAL_ 304 ST_LOKG_STCO 0 "Off" 1 "On" 2 "Signal Invalid";
VAL_ 304 ST_KLCK 0 "Off" 1 "On" 2 "Signal Invalid";
VAL_ 304 ST_PSVA_ACV 0 "Off" 1 "On" 2 "Signal Invalid";
VAL_ 304 ST_ILK_COD_BM 0 "Off" 1 "On" 2 "Signal Invalid";
VAL_ 416 ST_VEH_DVCO 0 "Vehicle Stationairy" 1 "Moving Forward" 2 "Moving Backward" 7 "Signal Invalid";
VAL_ 408 ShifterPosition 1 "D" 2 "S" 3 "N" 4 "R" 5 "P";
VAL_ 436 ST_UN_V_SPDM 0 "km/h" 1 "mph" 3 "Invalid Signal";
VAL_ 436 ST_INTF_CCTRA_KL 0 "OK" 1 "Error in Cluster" 2 "Error in ACC" 4 "Error in Cruise";
VAL_ 436 ST_WALI_ENG 0 "Off" 1 "MIL On" 3 "Signal Invalid";
VAL_ 466 ShiftLeverMode 0 "Normal" 1 "Sport" 2 "Manual";
VAL_ 466 ShiftLeverPosition 0 "Off" 1 "P" 2 "R" 4 "N" 8 "D";
VAL_ 437 CTR_AIC_RDI 0 "Switch Off" 1 "Switch On" 2 "Switch On Increase Speed 1" 4 "Switch On Increase Speed 2" 7 "Signal Invalid";
VAL_ 578 AC_button 0 "Off" 1 "On";
VAL_ 578 Blowers 0 "Off" 1 "On";
VAL_ 764 DOOR_STATUS 1 "FL Open" 4 "FR Open" 16 "RL Open" 64 "RR Open";
VAL_ 764 BOOT_BONNET_STATUS 1 "Boot Open" 4 "Bonnet Open";
VAL_ 816 ST_FLLV_FUTA_SPAR 0 "Off" 1 "On" 3 "Signal Invalid";
VAL_ 948 ST_BTSW 0 "Battery Switch Closed" 1 "Battery Switch Opening in 5s" 2 "Signal Invalid";
VAL_ 948 ST_SWO_KL_30 0 "Reserved" 1 "No Shutdown" 2 "Shutdown by PM" 3 "Signal Invalid";
VAL_ 847 ST_HandBrake_Cont 1 "Off" 2 "On" 3 "Signal Invalid";
VAL_ 944 ST_Reverse_Gear 1 "Off" 2 "On" 3 "Signal Invalid";
